# RZT2H register map
Vendor: Renesas Electronics Corporation; Series: RZT; File version: 1.00.00
CPU: other r0p0, little endian, MPU, no FPU, VTOR, 4 interrupt priority bits, 624 interrupts
Registers are 32-bit, read-write, reset 0x0 unless marked. A register's access mark holds for its fields unless they carry their own. Offsets are from the block's base; [hi:lo] are bit positions; {n}, {i} and the like mark numbered series; 'fields as' and 'values as' point back to an identical list.

## GMAC0
Base 0x80100000
Same registers: GMAC1 0x92000000, GMAC2 0x92010000
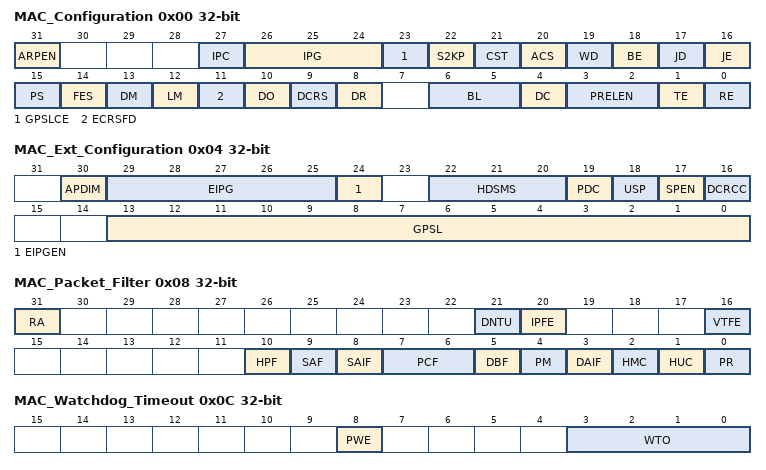
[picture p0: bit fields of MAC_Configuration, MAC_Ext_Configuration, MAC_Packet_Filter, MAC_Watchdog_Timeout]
0x00 MAC_Configuration
  [31] ARPEN, [27] IPC, [26:24] IPG, [23] GPSLCE, [22] S2KP, [21] CST, [20] ACS, [19] WD, [18] BE, [17] JD, [16] JE, [15] PS, [14] FES, [13] DM, [12] LM, [11] ECRSFD, [10] DO, [9] DCRS, [8] DR, [6:5] BL, [4] DC, [3:2] PRELEN, [1] TE, [0] RE
0x04 MAC_Ext_Configuration
  [30] APDIM, [29:25] EIPG, [24] EIPGEN, [22:20] HDSMS, [19] PDC, [18] USP, [17] SPEN, [16] DCRCC, [13:0] GPSL
0x08 MAC_Packet_Filter
  [31] RA, [21] DNTU, [20] IPFE, [16] VTFE, [10] HPF, [9] SAF, [8] SAIF, [7:6] PCF, [5] DBF, [4] PM, [3] DAIF, [2] HMC, [1] HUC, [0] PR
0x0C MAC_Watchdog_Timeout
  [8] PWE, [3:0] WTO
{0x10+4i} MAC_HASH_TABLE_REG{i} (i=0..7)
  [31:0] HT
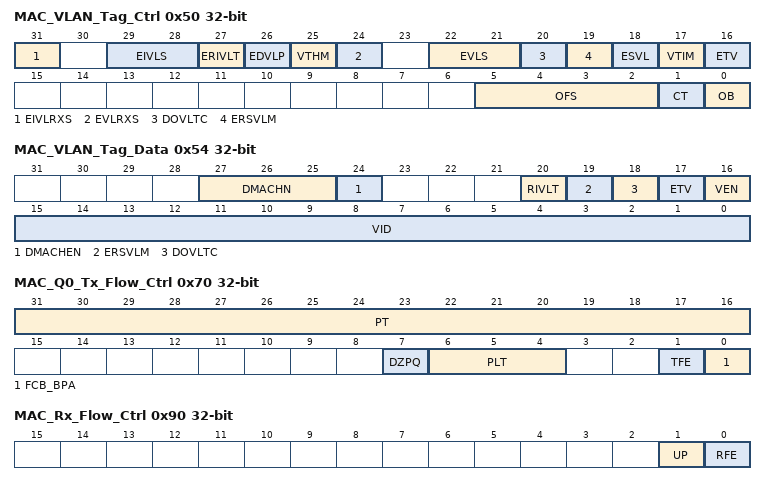
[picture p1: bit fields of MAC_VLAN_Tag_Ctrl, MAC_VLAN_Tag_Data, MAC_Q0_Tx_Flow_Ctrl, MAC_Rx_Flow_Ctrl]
0x50 MAC_VLAN_Tag_Ctrl
  [31] EIVLRXS, [29:28] EIVLS, [27] ERIVLT, [26] EDVLP, [25] VTHM, [24] EVLRXS, [22:21] EVLS, [20] DOVLTC, [19] ERSVLM, [18] ESVL, [17] VTIM, [16] ETV, [5:2] OFS, [1] CT, [0] OB
0x54 MAC_VLAN_Tag_Data
  [27:25] DMACHN, [24] DMACHEN, [20] RIVLT, [19] ERSVLM, [18] DOVLTC, [17] ETV, [16] VEN, [15:0] VID
0x58 MAC_VLAN_Hash_Table
  [15:0] VLHT
0x70 MAC_Q0_Tx_Flow_Ctrl
  [31:16] PT, [7] DZPQ, [6:4] PLT, [1] TFE, [0] FCB_BPA
0x90 MAC_Rx_Flow_Ctrl
  [1] UP, [0] RFE
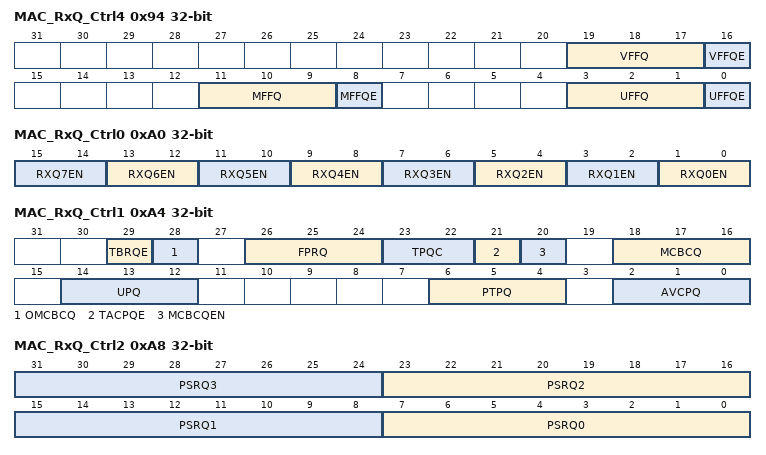
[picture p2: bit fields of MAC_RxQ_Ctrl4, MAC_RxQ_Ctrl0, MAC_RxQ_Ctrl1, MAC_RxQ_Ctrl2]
0x94 MAC_RxQ_Ctrl4
  [19:17] VFFQ, [16] VFFQE, [11:9] MFFQ, [8] MFFQE, [3:1] UFFQ, [0] UFFQE
0xA0 MAC_RxQ_Ctrl0
  [2n+1:2n] RXQ{n}EN (n=0..7)
0xA4 MAC_RxQ_Ctrl1
  [29] TBRQE, [28] OMCBCQ, [26:24] FPRQ, [23:22] TPQC, [21] TACPQE, [20] MCBCQEN, [18:16] MCBCQ, [14:12] UPQ, [6:4] PTPQ, [2:0] AVCPQ
0xA8 MAC_RxQ_Ctrl2
  [8n+7:8n] PSRQ{n} (n=0..3)
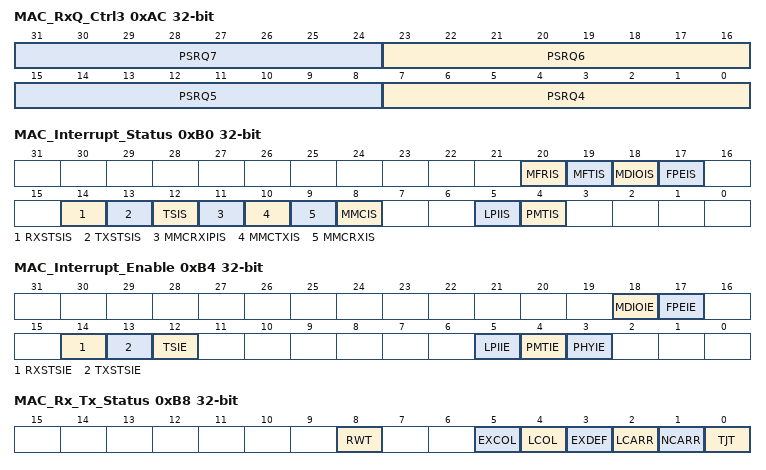
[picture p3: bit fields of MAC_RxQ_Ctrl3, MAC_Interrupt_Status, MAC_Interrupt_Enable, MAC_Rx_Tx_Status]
0xAC MAC_RxQ_Ctrl3
  [8n-25:8n-32] PSRQ{n} (n=4..7)
0xB0 MAC_Interrupt_Status ro
  [20] MFRIS, [19] MFTIS, [18] MDIOIS, [17] FPEIS, [14] RXSTSIS, [13] TXSTSIS, [12] TSIS, [11] MMCRXIPIS, [10] MMCTXIS, [9] MMCRXIS, [8] MMCIS, [5] LPIIS, [4] PMTIS
0xB4 MAC_Interrupt_Enable
  [18] MDIOIE, [17] FPEIE, [14] RXSTSIE, [13] TXSTSIE, [12] TSIE, [5] LPIIE, [4] PMTIE, [3] PHYIE
0xB8 MAC_Rx_Tx_Status ro
  [8] RWT, [5] EXCOL, [4] LCOL, [3] EXDEF, [2] LCARR, [1] NCARR, [0] TJT
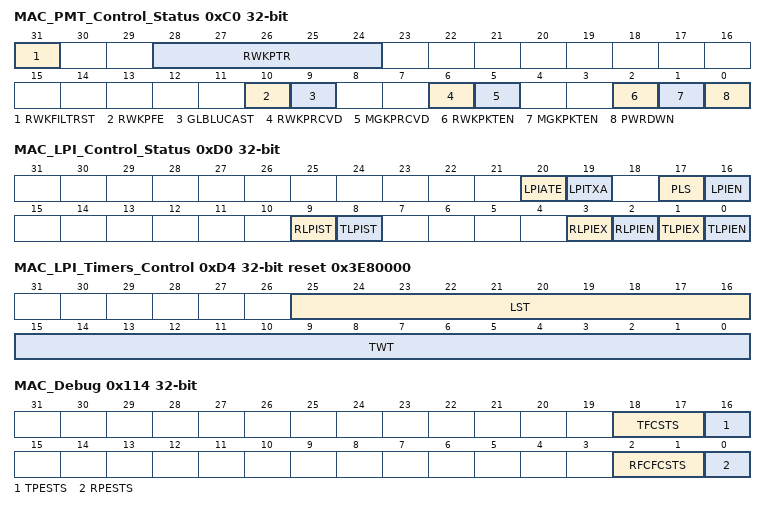
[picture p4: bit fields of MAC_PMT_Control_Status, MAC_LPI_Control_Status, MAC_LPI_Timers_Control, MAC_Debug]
0xC0 MAC_PMT_Control_Status
  [31] RWKFILTRST, [28:24] RWKPTR ro, [10] RWKPFE, [9] GLBLUCAST, [6] RWKPRCVD ro, [5] MGKPRCVD ro, [2] RWKPKTEN, [1] MGKPKTEN, [0] PWRDWN
0xC4 MAC_RWK_Packet_Filter
  [31:0] WKUPFRMFTR
0xD0 MAC_LPI_Control_Status
  [20] LPIATE, [19] LPITXA, [17] PLS, [16] LPIEN, [9] RLPIST ro, [8] TLPIST ro, [3] RLPIEX ro, [2] RLPIEN ro, [1] TLPIEX ro, [0] TLPIEN ro
0xD4 MAC_LPI_Timers_Control reset 0x3E80000
  [25:16] LST, [15:0] TWT
0xD8 MAC_LPI_Entry_Timer
  [19:3] LPIET
0xDC MAC_1US_Tic_Counter reset 0x63
  [11:0] TIC_1US_CNTR
0x110 MAC_Version ro reset 0x52
  [15:0] VER
0x114 MAC_Debug ro
  [18:17] TFCSTS, [16] TPESTS, [2:1] RFCFCSTS, [0] RPESTS
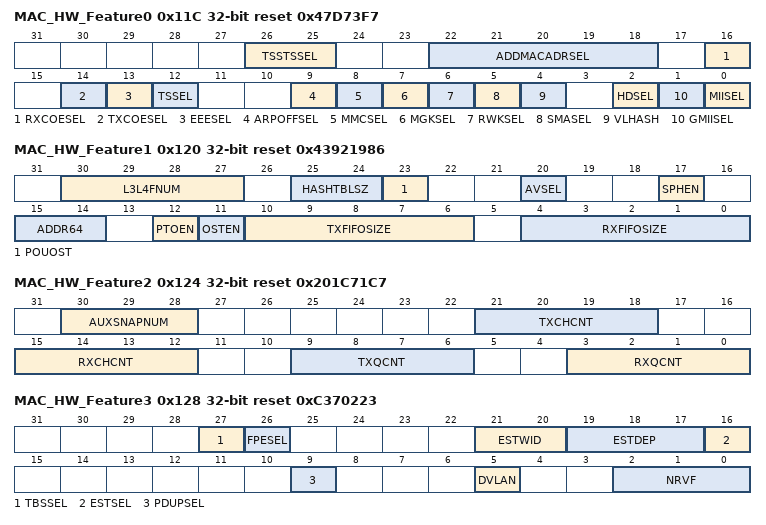
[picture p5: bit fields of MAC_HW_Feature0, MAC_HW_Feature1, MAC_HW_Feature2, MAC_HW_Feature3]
0x11C MAC_HW_Feature0 ro reset 0x47D73F7
  [26:25] TSSTSSEL, [22:18] ADDMACADRSEL, [16] RXCOESEL, [14] TXCOESEL, [13] EEESEL, [12] TSSEL, [9] ARPOFFSEL, [8] MMCSEL, [7] MGKSEL, [6] RWKSEL, [5] SMASEL, [4] VLHASH, [2] HDSEL, [1] GMIISEL, [0] MIISEL
0x120 MAC_HW_Feature1 ro reset 0x43921986
  [30:27] L3L4FNUM, [25:24] HASHTBLSZ, [23] POUOST, [20] AVSEL, [17] SPHEN, [15:14] ADDR64, [12] PTOEN, [11] OSTEN, [10:6] TXFIFOSIZE, [4:0] RXFIFOSIZE
0x124 MAC_HW_Feature2 ro reset 0x201C71C7
  [30:28] AUXSNAPNUM, [21:18] TXCHCNT, [15:12] RXCHCNT, [9:6] TXQCNT, [3:0] RXQCNT
0x128 MAC_HW_Feature3 ro reset 0xC370223
  [27] TBSSEL, [26] FPESEL, [21:20] ESTWID, [19:17] ESTDEP, [16] ESTSEL, [9] PDUPSEL, [5] DVLAN, [2:0] NRVF
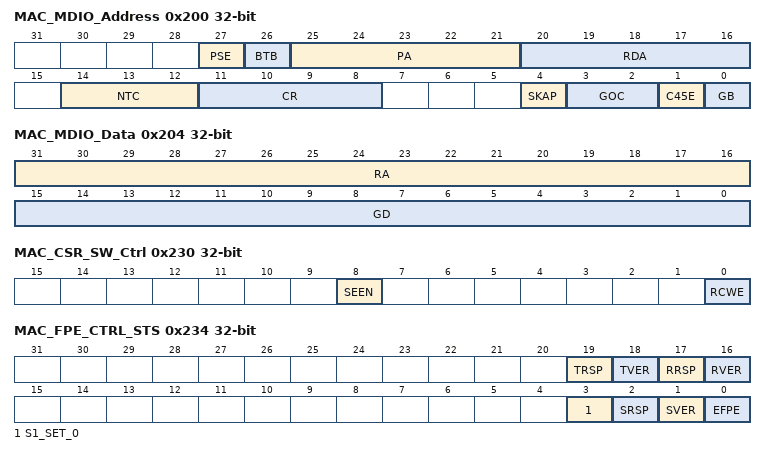
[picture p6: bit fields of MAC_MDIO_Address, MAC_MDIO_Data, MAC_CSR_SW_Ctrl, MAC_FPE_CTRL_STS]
0x200 MAC_MDIO_Address
  [27] PSE, [26] BTB, [25:21] PA, [20:16] RDA, [14:12] NTC, [11:8] CR, [4] SKAP, [3:2] GOC, [1] C45E, [0] GB
0x204 MAC_MDIO_Data
  [31:16] RA, [15:0] GD
0x210 MAC_ARP_Address
  [31:0] ARPPA
0x230 MAC_CSR_SW_Ctrl
  [8] SEEN, [0] RCWE
0x234 MAC_FPE_CTRL_STS
  [19] TRSP, [18] TVER, [17] RRSP, [16] RVER, [3] S1_SET_0, [2] SRSP, [1] SVER, [0] EFPE
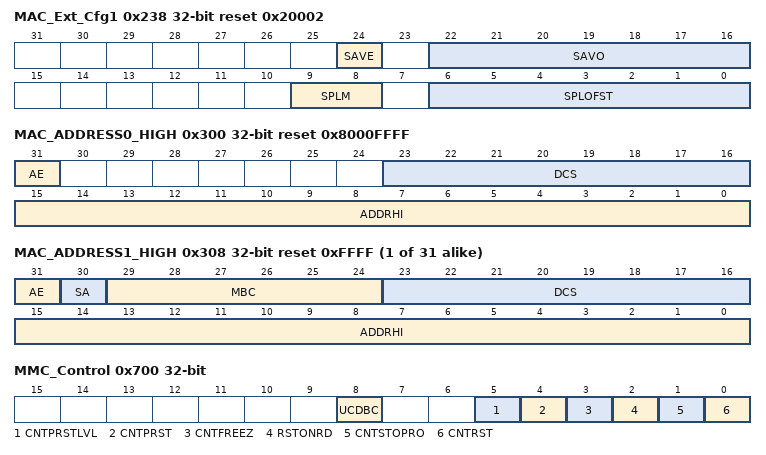
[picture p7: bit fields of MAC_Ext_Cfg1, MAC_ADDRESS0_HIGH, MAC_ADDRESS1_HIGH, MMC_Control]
0x238 MAC_Ext_Cfg1 reset 0x20002
  [24] SAVE, [22:16] SAVO, [9:8] SPLM, [6:0] SPLOFST
0x300 MAC_ADDRESS0_HIGH reset 0x8000FFFF
  [31] AE ro, [23:16] DCS, [15:0] ADDRHI
0x304 MAC_ADDRESS0_LOW reset 0xFFFFFFFF
  [31:0] ADDRLO
{0x300+8i} MAC_ADDRESS{i}_HIGH (i=1..31) reset 0xFFFF
  [31] AE, [30] SA, [29:24] MBC, [23:16] DCS, [15:0] ADDRHI
{0x304+8i} MAC_ADDRESS{i}_LOW (i=1..31) reset 0xFFFFFFFF
  [31:0] ADDRLO
0x700 MMC_Control
  [8] UCDBC, [5] CNTPRSTLVL, [4] CNTPRST, [3] CNTFREEZ, [2] RSTONRD, [1] CNTSTOPRO, [0] CNTRST
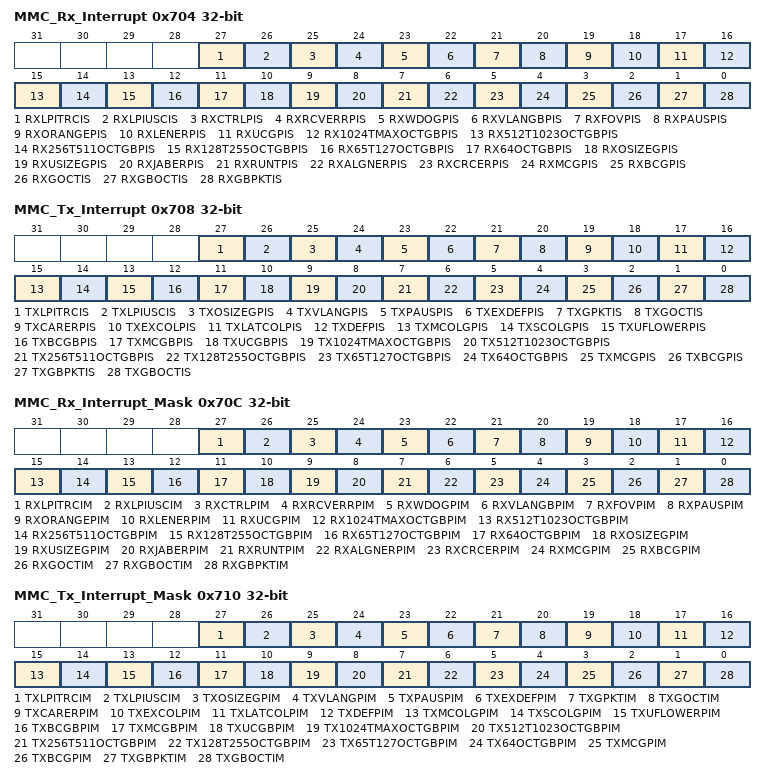
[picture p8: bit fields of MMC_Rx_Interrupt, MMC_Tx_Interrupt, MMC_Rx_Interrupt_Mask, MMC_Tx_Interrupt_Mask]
0x704 MMC_Rx_Interrupt ro
  [27] RXLPITRCIS, [26] RXLPIUSCIS, [25] RXCTRLPIS, [24] RXRCVERRPIS, [23] RXWDOGPIS, [22] RXVLANGBPIS, [21] RXFOVPIS, [20] RXPAUSPIS, [19] RXORANGEPIS, [18] RXLENERPIS, [17] RXUCGPIS, [16] RX1024TMAXOCTGBPIS, [15] RX512T1023OCTGBPIS, [14] RX256T511OCTGBPIS, [13] RX128T255OCTGBPIS, [12] RX65T127OCTGBPIS, [11] RX64OCTGBPIS, [10] RXOSIZEGPIS, [9] RXUSIZEGPIS, [8] RXJABERPIS, [7] RXRUNTPIS, [6] RXALGNERPIS, [5] RXCRCERPIS, [4] RXMCGPIS, [3] RXBCGPIS, [2] RXGOCTIS, [1] RXGBOCTIS, [0] RXGBPKTIS
0x708 MMC_Tx_Interrupt ro
  [27] TXLPITRCIS, [26] TXLPIUSCIS, [25] TXOSIZEGPIS, [24] TXVLANGPIS, [23] TXPAUSPIS, [22] TXEXDEFPIS, [21] TXGPKTIS, [20] TXGOCTIS, [19] TXCARERPIS, [18] TXEXCOLPIS, [17] TXLATCOLPIS, [16] TXDEFPIS, [15] TXMCOLGPIS, [14] TXSCOLGPIS, [13] TXUFLOWERPIS, [12] TXBCGBPIS, [11] TXMCGBPIS, [10] TXUCGBPIS, [9] TX1024TMAXOCTGBPIS, [8] TX512T1023OCTGBPIS, [7] TX256T511OCTGBPIS, [6] TX128T255OCTGBPIS, [5] TX65T127OCTGBPIS, [4] TX64OCTGBPIS, [3] TXMCGPIS, [2] TXBCGPIS, [1] TXGBPKTIS, [0] TXGBOCTIS
0x70C MMC_Rx_Interrupt_Mask
  [27] RXLPITRCIM, [26] RXLPIUSCIM, [25] RXCTRLPIM, [24] RXRCVERRPIM, [23] RXWDOGPIM, [22] RXVLANGBPIM, [21] RXFOVPIM, [20] RXPAUSPIM, [19] RXORANGEPIM, [18] RXLENERPIM, [17] RXUCGPIM, [16] RX1024TMAXOCTGBPIM, [15] RX512T1023OCTGBPIM, [14] RX256T511OCTGBPIM, [13] RX128T255OCTGBPIM, [12] RX65T127OCTGBPIM, [11] RX64OCTGBPIM, [10] RXOSIZEGPIM, [9] RXUSIZEGPIM, [8] RXJABERPIM, [7] RXRUNTPIM, [6] RXALGNERPIM, [5] RXCRCERPIM, [4] RXMCGPIM, [3] RXBCGPIM, [2] RXGOCTIM, [1] RXGBOCTIM, [0] RXGBPKTIM
0x710 MMC_Tx_Interrupt_Mask
  [27] TXLPITRCIM, [26] TXLPIUSCIM, [25] TXOSIZEGPIM, [24] TXVLANGPIM, [23] TXPAUSPIM, [22] TXEXDEFPIM, [21] TXGPKTIM, [20] TXGOCTIM, [19] TXCARERPIM, [18] TXEXCOLPIM, [17] TXLATCOLPIM, [16] TXDEFPIM, [15] TXMCOLGPIM, [14] TXSCOLGPIM, [13] TXUFLOWERPIM, [12] TXBCGBPIM, [11] TXMCGBPIM, [10] TXUCGBPIM, [9] TX1024TMAXOCTGBPIM, [8] TX512T1023OCTGBPIM, [7] TX256T511OCTGBPIM, [6] TX128T255OCTGBPIM, [5] TX65T127OCTGBPIM, [4] TX64OCTGBPIM, [3] TXMCGPIM, [2] TXBCGPIM, [1] TXGBPKTIM, [0] TXGBOCTIM
0x714 Tx_Octet_Count_Good_Bad ro
  [31:0] TXOCTGB
0x718 Tx_Packet_Count_Good_Bad ro
  [31:0] TXPKTGB
0x71C Tx_Broadcast_Packets_Good ro
  [31:0] TXBCASTG
0x720 Tx_Multicast_Packets_Good ro
  [31:0] TXMCASTG
0x724 Tx_64Octets_Packets_Good_Bad ro
  [31:0] TX64OCTGB
0x728 Tx_65To127Octets_Packets_Good_Bad ro
  [31:0] TX65_127OCTGB
0x72C Tx_128To255Octets_Packets_Good_Bad ro
  [31:0] TX128_255OCTGB
0x730 Tx_256To511Octets_Packets_Good_Bad ro
  [31:0] TX256_511OCTGB
0x734 Tx_512To1023Octets_Packets_Good_Bad ro
  [31:0] TX512_1023OCTGB
0x738 Tx_1024ToMaxOctets_Packets_Good_Bad ro
  [31:0] TX1024_MAXOCTGB
0x73C Tx_Unicast_Packets_Good_Bad ro
  [31:0] TXUCASTGB
0x740 Tx_Multicast_Packets_Good_Bad ro
  [31:0] TXMCASTGB
0x744 Tx_Broadcast_Packets_Good_Bad ro
  [31:0] TXBCASTGB
0x748 Tx_Underflow_Error_Packets ro
  [31:0] TXUNDRFLW
0x74C Tx_Single_Collision_Good_Packets ro
  [31:0] TXSNGLCOLG
0x750 Tx_Multiple_Collision_Good_Packets ro
  [31:0] TXMULTCOLG
0x754 Tx_Deferred_Packets ro
  [31:0] TXDEFRD
0x758 Tx_Late_Collision_Packets ro
  [31:0] TXLATECOL
0x75C Tx_Excessive_Collision_Packets ro
  [31:0] TXEXSCOL
0x760 Tx_Carrier_Error_Packets ro
  [31:0] TXCARR
0x764 Tx_Octet_Count_Good ro
  [31:0] TXOCTG
0x768 Tx_Packet_Count_Good ro
  [31:0] TXPKTG
0x76C Tx_Excessive_Deferral_Error ro
  [31:0] TXEXSDEF
0x770 Tx_Pause_Packets ro
  [31:0] TXPAUSE
0x774 Tx_VLAN_Packets_Good ro
  [31:0] TXVLANG
0x778 Tx_OSize_Packets_Good ro
  [31:0] TXOSIZG
0x780 Rx_Packets_Count_Good_Bad ro
  [31:0] RXPKTGB
0x784 Rx_Octet_Count_Good_Bad ro
  [31:0] RXOCTGB
0x788 Rx_Octet_Count_Good ro
  [31:0] RXOCTG
0x78C Rx_Broadcast_Packets_Good ro
  [31:0] RXBCASTG
0x790 Rx_Multicast_Packets_Good ro
  [31:0] RXMCASTG
0x794 Rx_CRC_Error_Packets ro
  [31:0] RXCRCERR
0x798 Rx_Alignment_Error_Packets ro
  [31:0] RXALGNERR
0x79C Rx_Runt_Error_Packets ro
  [31:0] RXRUNTERR
0x7A0 Rx_Jabber_Error_Packets ro
  [31:0] RXJABERR
0x7A4 Rx_Undersize_Packets_Good ro
  [31:0] RXUNDERSZG
0x7A8 Rx_Oversize_Packets_Good ro
  [31:0] RXOVERSZG
0x7AC Rx_64Octets_Packets_Good_Bad ro
  [31:0] RX64OCTGB
0x7B0 Rx_65To127Octets_Packets_Good_Bad ro
  [31:0] RX65_127OCTGB
0x7B4 Rx_128To255Octets_Packets_Good_Bad ro
  [31:0] RX128_255OCTGB
0x7B8 Rx_256To511Octets_Packets_Good_Bad ro
  [31:0] RX256_511OCTGB
0x7BC Rx_512To1023Octets_Packets_Good_Bad ro
  [31:0] RX512_1023OCTGB
0x7C0 Rx_1024ToMaxOctets_Packets_Good_Bad ro
  [31:0] RX1024_MAXOCTGB
0x7C4 Rx_Unicast_Packets_Good ro
  [31:0] RXUCASTG
0x7C8 Rx_Length_Error_Packets ro
  [31:0] RXLENERR
0x7CC Rx_Out_Of_Range_Type_Packets ro
  [31:0] RXOUTOFRNG
0x7D0 Rx_Pause_Packets ro
  [31:0] RXPAUSEPKT
0x7D4 Rx_FIFO_Overflow_Packets ro
  [31:0] RXFIFOOVFL
0x7D8 Rx_VLAN_Packets_Good_Bad ro
  [31:0] RXVLANPKTGB
0x7DC Rx_Watchdog_Error_Packets ro
  [31:0] RXWDGERR
0x7E0 Rx_Receive_Error_Packets ro
  [31:0] RXRCVERR
0x7E4 Rx_Control_Packets_Good ro
  [31:0] RXCTRLG
0x7EC Tx_LPI_USEC_Cntr ro
  [31:0] TXLPIUSC
0x7F0 Tx_LPI_Tran_Cntr ro
  [31:0] TXLPITRC
0x7F4 Rx_LPI_USEC_Cntr ro
  [31:0] RXLPIUSC
0x7F8 Rx_LPI_Tran_Cntr ro
  [31:0] RXLPITRC
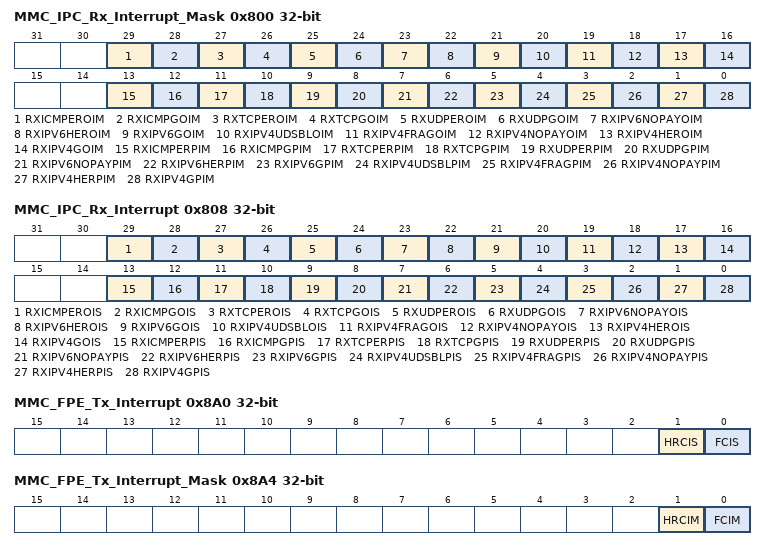
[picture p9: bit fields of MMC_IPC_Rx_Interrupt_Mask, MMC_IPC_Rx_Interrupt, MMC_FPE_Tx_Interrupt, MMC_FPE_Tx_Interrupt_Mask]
0x800 MMC_IPC_Rx_Interrupt_Mask
  [29] RXICMPEROIM, [28] RXICMPGOIM, [27] RXTCPEROIM, [26] RXTCPGOIM, [25] RXUDPEROIM, [24] RXUDPGOIM, [23] RXIPV6NOPAYOIM, [22] RXIPV6HEROIM, [21] RXIPV6GOIM, [20] RXIPV4UDSBLOIM, [19] RXIPV4FRAGOIM, [18] RXIPV4NOPAYOIM, [17] RXIPV4HEROIM, [16] RXIPV4GOIM, [13] RXICMPERPIM, [12] RXICMPGPIM, [11] RXTCPERPIM, [10] RXTCPGPIM, [9] RXUDPERPIM, [8] RXUDPGPIM, [7] RXIPV6NOPAYPIM, [6] RXIPV6HERPIM, [5] RXIPV6GPIM, [4] RXIPV4UDSBLPIM, [3] RXIPV4FRAGPIM, [2] RXIPV4NOPAYPIM, [1] RXIPV4HERPIM, [0] RXIPV4GPIM
0x808 MMC_IPC_Rx_Interrupt ro
  [29] RXICMPEROIS, [28] RXICMPGOIS, [27] RXTCPEROIS, [26] RXTCPGOIS, [25] RXUDPEROIS, [24] RXUDPGOIS, [23] RXIPV6NOPAYOIS, [22] RXIPV6HEROIS, [21] RXIPV6GOIS, [20] RXIPV4UDSBLOIS, [19] RXIPV4FRAGOIS, [18] RXIPV4NOPAYOIS, [17] RXIPV4HEROIS, [16] RXIPV4GOIS, [13] RXICMPERPIS, [12] RXICMPGPIS, [11] RXTCPERPIS, [10] RXTCPGPIS, [9] RXUDPERPIS, [8] RXUDPGPIS, [7] RXIPV6NOPAYPIS, [6] RXIPV6HERPIS, [5] RXIPV6GPIS, [4] RXIPV4UDSBLPIS, [3] RXIPV4FRAGPIS, [2] RXIPV4NOPAYPIS, [1] RXIPV4HERPIS, [0] RXIPV4GPIS
0x810 RxIPv4_Good_Packets ro
  [31:0] RXIPV4GDPKT
0x814 RxIPv4_Header_Error_Packets ro
  [31:0] RXIPV4HDRERRPKT
0x818 RxIPv4_No_Payload_Packets ro
  [31:0] RXIPV4NOPAYPKT
0x81C RxIPv4_Fragmented_Packets ro
  [31:0] RXIPV4FRAGPKT
0x820 RxIPv4_UDP_Checksum_Disabled_Packets ro
  [31:0] RXIPV4UDSBLPKT
0x824 RxIPv6_Good_Packets ro
  [31:0] RXIPV6GDPKT
0x828 RxIPv6_Header_Error_Packets ro
  [31:0] RXIPV6HDRERRPKT
0x82C RxIPv6_No_Payload_Packets ro
  [31:0] RXIPV6NOPAYPKT
0x830 RxUDP_Good_Packets ro
  [31:0] RXUDPGDPKT
0x834 RxUDP_Error_Packets ro
  [31:0] RXUDPERRPKT
0x838 RxTCP_Good_Packets ro
  [31:0] RXTCPGDPKT
0x83C RxTCP_Error_Packets ro
  [31:0] RXTCPERRPKT
0x840 RxICMP_Good_Packets ro
  [31:0] RXICMPGDPKT
0x844 RxICMP_Error_Packets ro
  [31:0] RXICMPERRPKT
0x850 RxIPv4_Good_Octets ro
  [31:0] RXIPV4GDOCT
0x854 RxIPv4_Header_Error_Octets ro
  [31:0] RXIPV4HDRERROCT
0x858 RxIPv4_No_Payload_Octets ro
  [31:0] RXIPV4NOPAYOCT
0x85C RxIPv4_Fragmented_Octets ro
  [31:0] RXIPV4FRAGOCT
0x860 RxIPv4_UDP_Checksum_Disable_Octets ro
  [31:0] RXIPV4UDSBLOCT
0x864 RxIPv6_Good_Octets ro
  [31:0] RXIPV6GDOCT
0x868 RxIPv6_Header_Error_Octets ro
  [31:0] RXIPV6HDRERROCT
0x86C RxIPv6_No_Payload_Octets ro
  [31:0] RXIPV6NOPAYOCT
0x870 RxUDP_Good_Octets ro
  [31:0] RXUDPGDOCT
0x874 RxUDP_Error_Octets ro
  [31:0] RXUDPERROCT
0x878 RxTCP_Good_Octets ro
  [31:0] RXTCPGDOCT
0x87C RxTCP_Error_Octets ro
  [31:0] RXTCPERROCT
0x880 RxICMP_Good_Octets ro
  [31:0] RXICMPGDOCT
0x884 RxICMP_Error_Octets ro
  [31:0] RXICMPERROCT
0x8A0 MMC_FPE_Tx_Interrupt ro
  [1] HRCIS, [0] FCIS
0x8A4 MMC_FPE_Tx_Interrupt_Mask
  [1] HRCIM, [0] FCIM
0x8A8 MMC_Tx_FPE_Fragment_Cntr ro
  [31:0] TXFFC
0x8AC MMC_Tx_Hold_Req_Cntr ro
  [31:0] TXHRC
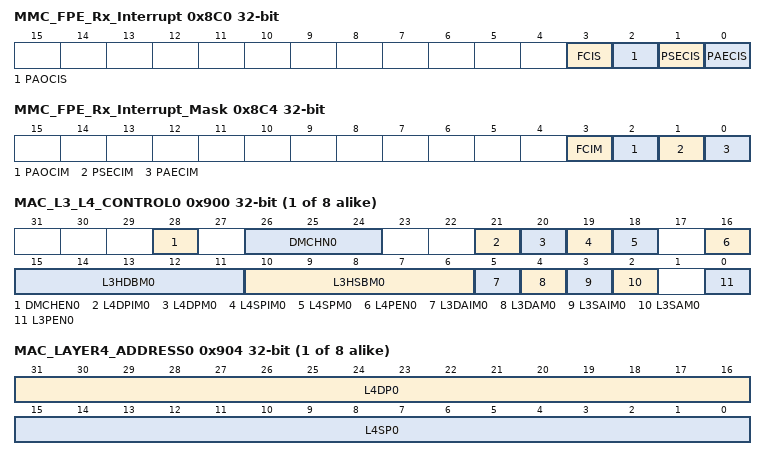
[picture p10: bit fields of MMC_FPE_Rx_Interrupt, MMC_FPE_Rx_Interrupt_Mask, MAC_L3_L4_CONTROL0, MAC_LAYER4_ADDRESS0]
0x8C0 MMC_FPE_Rx_Interrupt ro
  [3] FCIS, [2] PAOCIS, [1] PSECIS, [0] PAECIS
0x8C4 MMC_FPE_Rx_Interrupt_Mask
  [3] FCIM, [2] PAOCIM, [1] PSECIM, [0] PAECIM
0x8C8 MMC_Rx_Packet_Assembly_Err_Cntr ro
  [31:0] PAEC
0x8CC MMC_Rx_Packet_SMD_Err_Cntr ro
  [31:0] PSEC
0x8D0 MMC_Rx_Packet_Assembly_OK_Cntr ro
  [31:0] PAOC
0x8D4 MMC_Rx_FPE_Fragment_Cntr ro
  [31:0] FFC
{0x900+0x30*i} MAC_L3_L4_CONTROL{i} (i=0..7)
  [28] DMCHEN0, [26:24] DMCHN0, [21] L4DPIM0, [20] L4DPM0, [19] L4SPIM0, [18] L4SPM0, [16] L4PEN0, [15:11] L3HDBM0, [10:6] L3HSBM0, [5] L3DAIM0, [4] L3DAM0, [3] L3SAIM0, [2] L3SAM0, [0] L3PEN0
{0x904+0x30*i} MAC_LAYER4_ADDRESS{i} (i=0..7)
  [31:16] L4DP0, [15:0] L4SP0
{0x910+0x30*i} MAC_LAYER3_ADDR0_REG{i} (i=0..7)
  [31:0] L3A00
{0x914+0x30*i} MAC_LAYER3_ADDR1_REG{i} (i=0..7)
  [31:0] L3A10
{0x918+0x30*i} MAC_LAYER3_ADDR2_REG{i} (i=0..7)
  [31:0] L3A20
{0x91C+0x30*i} MAC_LAYER3_ADDR3_REG{i} (i=0..7)
  [31:0] L3A30
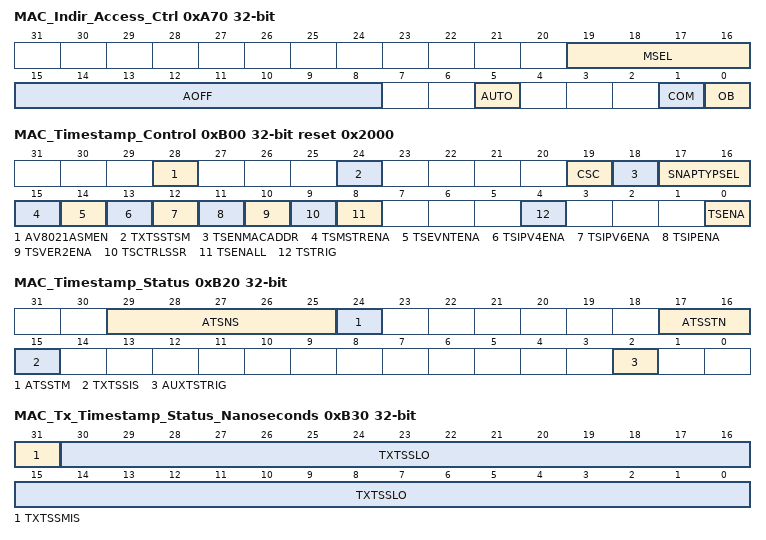
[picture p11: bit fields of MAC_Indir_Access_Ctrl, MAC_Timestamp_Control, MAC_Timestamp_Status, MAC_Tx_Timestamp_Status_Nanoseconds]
0xA70 MAC_Indir_Access_Ctrl
  [19:16] MSEL, [15:8] AOFF, [5] AUTO, [1] COM, [0] OB
0xA74 MAC_Indir_Access_Data
0xB00 MAC_Timestamp_Control reset 0x2000
  [28] AV8021ASMEN, [24] TXTSSTSM, [19] CSC, [18] TSENMACADDR, [17:16] SNAPTYPSEL, [15] TSMSTRENA, [14] TSEVNTENA, [13] TSIPV4ENA, [12] TSIPV6ENA, [11] TSIPENA, [10] TSVER2ENA, [9] TSCTRLSSR, [8] TSENALL, [4] TSTRIG, [0] TSENA
0xB08 MAC_System_Time_Seconds ro
  [31:0] TSS
0xB0C MAC_System_Time_Nanoseconds ro
  [30:0] TSSS
0xB20 MAC_Timestamp_Status ro
  [29:25] ATSNS, [24] ATSSTM, [17:16] ATSSTN, [15] TXTSSIS, [2] AUXTSTRIG
0xB30 MAC_Tx_Timestamp_Status_Nanoseconds ro
  [31] TXTSSMIS, [30:0] TXTSSLO
0xB34 MAC_Tx_Timestamp_Status_Seconds ro
  [31:0] TXTSSHI
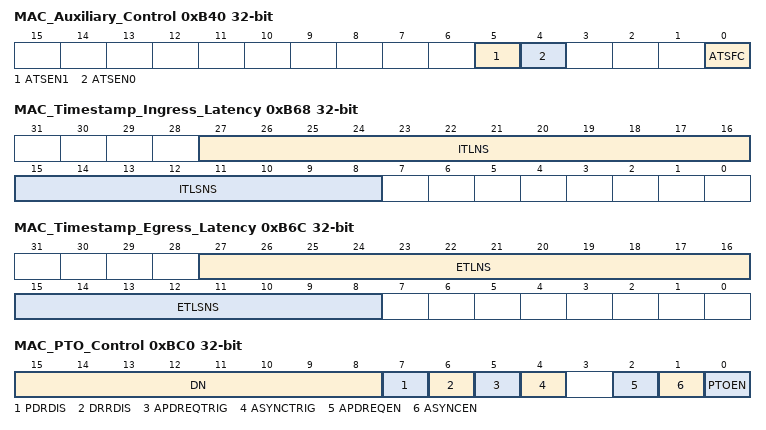
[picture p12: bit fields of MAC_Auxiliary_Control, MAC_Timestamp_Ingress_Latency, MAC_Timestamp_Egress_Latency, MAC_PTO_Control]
0xB40 MAC_Auxiliary_Control
  [5] ATSEN1, [4] ATSEN0, [0] ATSFC
0xB48 MAC_Auxiliary_Timestamp_Nanoseconds ro
  [30:0] AUXTSLO
0xB4C MAC_Auxiliary_Timestamp_Seconds ro
  [31:0] AUXTSHI
0xB50 MAC_Timestamp_Ingress_Asym_Corr
  [31:0] OSTIAC
0xB54 MAC_Timestamp_Egress_Asym_Corr
  [31:0] OSTEAC
0xB58 MAC_Timestamp_Ingress_Corr_Nanosecond
  [31:0] TSIC
0xB5C MAC_Timestamp_Egress_Corr_Nanosecond
  [31:0] TSEC
0xB60 MAC_Timestamp_Ingress_Corr_Subnanosec
  [15:8] TSICSNS
0xB64 MAC_Timestamp_Egress_Corr_Subnanosec
  [15:8] TSECSNS
0xB68 MAC_Timestamp_Ingress_Latency ro
  [27:16] ITLNS, [15:8] ITLSNS
0xB6C MAC_Timestamp_Egress_Latency ro
  [27:16] ETLNS, [15:8] ETLSNS
0xBC0 MAC_PTO_Control
  [15:8] DN, [7] PDRDIS, [6] DRRDIS, [5] APDREQTRIG, [4] ASYNCTRIG, [2] APDREQEN, [1] ASYNCEN, [0] PTOEN
0xBC4 MAC_Source_Port_Identity0
  [31:0] SPI0
0xBC8 MAC_Source_Port_Identity1
  [31:0] SPI1
0xBCC MAC_Source_Port_Identity2
  [15:0] SPI2
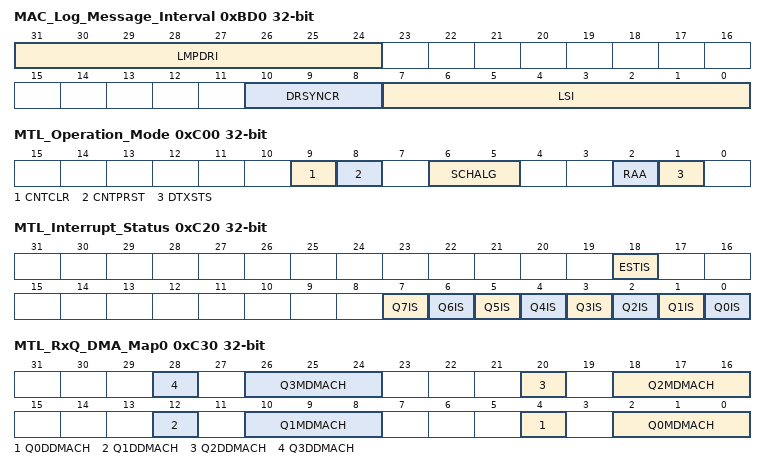
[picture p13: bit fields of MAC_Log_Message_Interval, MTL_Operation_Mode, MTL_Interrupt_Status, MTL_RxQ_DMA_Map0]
0xBD0 MAC_Log_Message_Interval
  [31:24] LMPDRI, [10:8] DRSYNCR, [7:0] LSI
0xC00 MTL_Operation_Mode
  [9] CNTCLR, [8] CNTPRST, [6:5] SCHALG, [2] RAA, [1] DTXSTS
0xC20 MTL_Interrupt_Status ro
  [18] ESTIS, [n] Q{n}IS (n=0..7)
0xC30 MTL_RxQ_DMA_Map0
  [8n+4] Q{n}DDMACH (n=0..3), [8n+2:8n] Q{n}MDMACH (n=0..3)
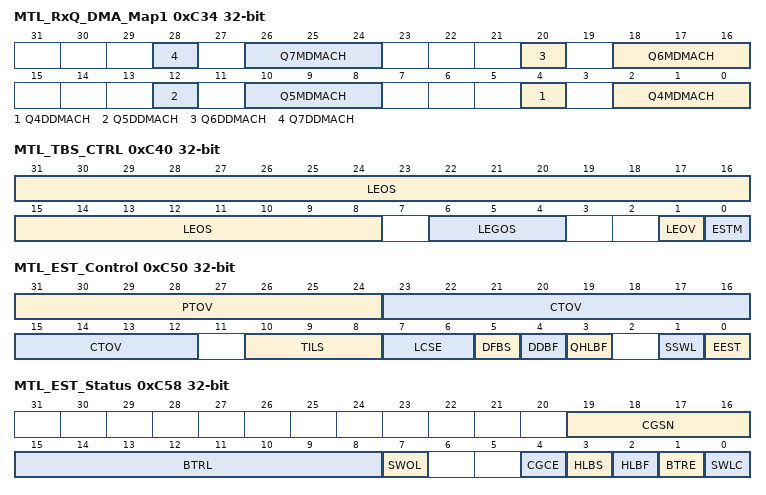
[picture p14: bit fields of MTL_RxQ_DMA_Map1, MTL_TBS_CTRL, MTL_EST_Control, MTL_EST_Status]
0xC34 MTL_RxQ_DMA_Map1
  [8n-28] Q{n}DDMACH (n=4..7), [8n-30:8n-32] Q{n}MDMACH (n=4..7)
0xC40 MTL_TBS_CTRL
  [31:8] LEOS, [6:4] LEGOS, [1] LEOV, [0] ESTM
0xC50 MTL_EST_Control
  [31:24] PTOV, [23:12] CTOV, [10:8] TILS, [7:6] LCSE, [5] DFBS, [4] DDBF, [3] QHLBF, [1] SSWL, [0] EEST
0xC54 MTL_EST_Ext_Control
  [5:0] OVHD
0xC58 MTL_EST_Status
  [19:16] CGSN ro, [15:8] BTRL ro, [7] SWOL ro, [4] CGCE, [3] HLBS ro, [2] HLBF ro, [1] BTRE, [0] SWLC
0xC60 MTL_EST_Sch_Error
  [7:0] SEQN
0xC64 MTL_EST_Frm_Size_Error
  [7:0] FEQN
0xC68 MTL_EST_Frm_Size_Capture ro
  [18:16] HBFQ, [14:0] HBFS
0xC70 MTL_EST_Intr_Enable
  [4] CGCE, [3] IEHS, [2] IEHF, [1] IEBE, [0] IECC
0xC80 MTL_EST_GCL_Control
  [15:8] ADDR, [5] DBGB, [4] DBGM, [2] GCRR, [1] R1W0, [0] SRWO
0xC84 MTL_EST_GCL_Data
  [31:0] GCD
0xC90 MTL_FPE_CTRL_STS
  [28] HRS ro, [15:8] PEC, [1:0] AFSZ
0xC94 MTL_FPE_Advance
  [31:16] RADV, [15:0] HADV
0xD00 MTL_TXQ0_OPERATION_MODE
  [20:16] TQS, [6:4] TTC, [3:2] TXQEN, [1] TSF, [0] FTQ
0xD04 MTL_TXQ0_UNDERFLOW ro
  [11] UFCNTOVF, [10:0] UFFRMCNT
0xD08 MTL_TXQ0_DEBUG ro
  [22:20] STXSTSF, [18:16] PTXQ, [5] TXSTSFSTS, [4] TXQSTS, [3] TWCSTS, [2:1] TRCSTS, [0] TXQPAUSED
0xD14 MTL_TXQ0_ETS_STATUS ro
  [23:0] ABS
0xD18 MTL_TXQ0_QUANTUM_WEIGHT
  [20:0] ISCQW
0xD2C MTL_Q0_INTERRUPT_CONTROL_STATUS
  [24] RXOIE, [16] RXOVFIS, [9] ABPSIE, [8] TXUIE, [1] ABPSIS, [0] TXUNFIS
0xD30 MTL_RXQ0_OPERATION_MODE
  [24:20] RQS, [17:14] RFD, [11:8] RFA, [7] EHFC, [6] DIS_TCP_EF, [5] RSF, [4] FEP, [3] FUP, [1:0] RTC
0xD34 MTL_RXQ0_MISSED_PACKET_OVERFLOW_CNT ro
  [27] MISCNTOVF, [26:16] MISPKTCNT, [11] OVFCNTOVF, [10:0] OVFPKTCNT
0xD38 MTL_RXQ0_DEBUG ro
  [29:16] PRXQ, [5:4] RXQSTS, [2:1] RRCSTS, [0] RWCSTS
0xD3C MTL_RXQ0_CONTROL
  [3] RXQ_FRM_ARBIT, [2:0] RXQ_WEGT
{0xD00+0x40*i} MTL_TXQ{i}_OPERATION_MODE (i=1..7)
  [20:16] TQS, [6:4] TTC, [3:2] TXQEN, [1] TSF, [0] FTQ
{0xD04+0x40*i} MTL_TXQ{i}_UNDERFLOW (i=1..7) ro
  [11] UFCNTOVF, [10:0] UFFRMCNT
{0xD08+0x40*i} MTL_TXQ{i}_DEBUG (i=1..7) ro
  fields as MTL_TXQ0_DEBUG
{0xD10+0x40*i} MTL_TXQ{i}_ETS_CONTROL (i=1..7)
  [6:4] SLC, [3] CC, [2] AVALG
{0xD14+0x40*i} MTL_TXQ{i}_ETS_STATUS (i=1..7) ro
  [23:0] ABS
{0xD18+0x40*i} MTL_TXQ{i}_QUANTUM_WEIGHT (i=1..7)
  [20:0] ISCQW
{0xD1C+0x40*i} MTL_TXQ{i}_SENDSLOPECREDIT (i=1..7)
  [13:0] SSC
{0xD20+0x40*i} MTL_TXQ{i}_HICREDIT (i=1..7)
  [28:0] HC
{0xD24+0x40*i} MTL_TXQ{i}_LOCREDIT (i=1..7)
  [28:0] LC
{0xD2C+0x40*i} MTL_Q{i}_INTERRUPT_CONTROL_STATUS (i=1..7)
  fields as MTL_Q0_INTERRUPT_CONTROL_STATUS
{0xD30+0x40*i} MTL_RXQ{i}_OPERATION_MODE (i=1..7)
  fields as MTL_RXQ0_OPERATION_MODE
{0xD34+0x40*i} MTL_RXQ{i}_MISSED_PACKET_OVERFLOW_CNT (i=1..7) ro
  [27] MISCNTOVF, [26:16] MISPKTCNT, [11] OVFCNTOVF, [10:0] OVFPKTCNT
{0xD38+0x40*i} MTL_RXQ{i}_DEBUG (i=1..7) ro
  [29:16] PRXQ, [5:4] RXQSTS, [2:1] RRCSTS, [0] RWCSTS
{0xD3C+0x40*i} MTL_RXQ{i}_CONTROL (i=1..7)
  [3] RXQ_FRM_ARBIT, [2:0] RXQ_WEGT
0x1000 DMA_Mode
  [17:16] INTM, [11] TXPR, [8] DSPW, [4:2] TAA, [0] SWR
0x1004 DMA_SysBus_Mode reset 0x1010000
  [31] EN_LPI, [30] LPI_XIT_PKT, [27:24] WR_OSR_LMT, [19:16] RD_OSR_LMT, [13] ONEKBBE, [12] AAL, [10] AALE, [3] BLEN16, [2] BLEN8, [1] BLEN4, [0] FB
0x1008 DMA_Interrupt_Status ro
  [17] MACIS, [16] MTLIS, [n] DC{n}IS (n=0..7)
0x100C DMA_Debug_Status0 ro
  [31:28] TPS2, [27:24] RPS2, [23:20] TPS1, [19:16] RPS1, [15:12] TPS0, [11:8] RPS0, [1] AXRHSTS, [0] AXWHSTS
0x1010 DMA_Debug_Status1 ro
  [8n-17:8n-20] TPS{n} (n=3..6), [8n-21:8n-24] RPS{n} (n=3..6)
0x1014 DMA_Debug_Status2 ro
  [7:4] TPS7, [3:0] RPS7
0x1040 AXI_LPI_Entry_Interval
  [3:0] LPIEI
{0x1050+4i} DMA_TBS_CTRL{i} (i=0..3)
  [31:8] FTOS, [6:4] FGOS, [0] FTOV
{0x1100+0x80*i} DMA_CH{i}_CONTROL (i=0..7)
  [24] SPH, [20:18] DSL
{0x1104+0x80*i} DMA_CH{i}_TX_CONTROL (i=0..7)
  [30:29] TFSEL, [28] EDSE, [21:16] TxPBL, [15] IPBL, [4] OSF, [3:1] TCW, [0] ST
{0x1108+0x80*i} DMA_CH{i}_RX_CONTROL (i=0..7)
  [31] RPF, [21:16] RxPBL, [14:5] RBSZ_13_y, [4:1] RBSZ_x_0 ro, [0] SR
{0x1114+0x80*i} DMA_CH{i}_TXDESC_LIST_ADDRESS (i=0..7)
  [31:0] TDESLA
{0x111C+0x80*i} DMA_CH{i}_RXDESC_LIST_ADDRESS (i=0..7)
  [31:0] RDESLA
{0x1120+0x80*i} DMA_CH{i}_TXDESC_TAIL_POINTER (i=0..7)
  [31:0] TDTP
{0x1128+0x80*i} DMA_CH{i}_RXDESC_TAIL_POINTER (i=0..7)
  [31:0] RDTP
{0x112C+0x80*i} DMA_CH{i}_TXDESC_RING_LENGTH (i=0..7)
  [9:0] TDRL
{0x1130+0x80*i} DMA_CH{i}_RX_CONTROL2 (i=0..7)
  [23:18] ARBS, [9:0] RDRL
{0x1134+0x80*i} DMA_CH{i}_INTERRUPT_ENABLE (i=0..7)
  [15] NIE, [14] AIE, [13] CDEE, [12] FBEE, [11] ERIE, [10] ETIE, [9] RWTE, [8] RSE, [7] RBUE, [6] RIE, [2] TBUE, [1] TXSE, [0] TIE
{0x1138+0x80*i} DMA_CH{i}_RX_INTERRUPT_WATCHDOG_TIMER (i=0..7)
  [17:16] RWTU, [7:0] RWT
{0x113C+0x80*i} DMA_CH{i}_SLOT_FUNCTION_CONTROL_STATUS (i=0..7) reset 0x7C0
  [19:16] RSN ro, [15:4] SIV, [1] ASC, [0] ESC
{0x1144+0x80*i} DMA_CH{i}_CURRENT_APP_TXDESC (i=0..7) ro
  [31:0] CURTDESAPTR
{0x114C+0x80*i} DMA_CH{i}_CURRENT_APP_RXDESC (i=0..7) ro
  [31:0] CURRDESAPTR
{0x1154+0x80*i} DMA_CH{i}_CURRENT_APP_TXBUFFER (i=0..7) ro
  [31:0] CURTBUFAPTR
{0x115C+0x80*i} DMA_CH{i}_CURRENT_APP_RXBUFFER (i=0..7) ro
  [31:0] CURRBUFAPTR
{0x1160+0x80*i} DMA_CH{i}_STATUS (i=0..7)
  [21:19] REB ro, [18:16] TEB ro, [15] NIS, [14] AIS, [13] CDE, [12] FBE, [11] ERI, [10] ETI, [9] RWT, [8] RPS, [7] RBU, [6] RI, [2] TBU, [1] TPS, [0] TI
{0x1164+0x80*i} DMA_CH{i}_MISS_FRAME_CNT (i=0..7) ro
  [15] MFCO, [10:0] MFC
